AUTOSAR XML (schema 4-2-2)
package /CDD_CORE5
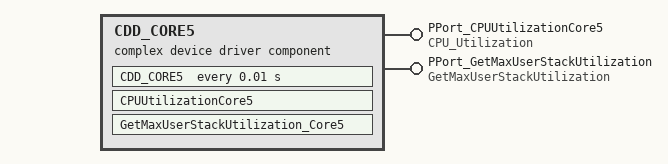
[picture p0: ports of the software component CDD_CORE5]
  complex device driver sw component type CDD_CORE5
    provide port PPort_CPUUtilizationCore5: provided-interface=CPU_Utilization
    provide port PPort_GetMaxUserStackUtilization: provided-interface=GetMaxUserStackUtilization
    behavior SwcInternalBehavior
      operation invoked event OperationInvokedEvent_0: start-on-event=CPUUtilizationCore5, operation=PPort_CPUUtilizationCore5.CPU_Utilization
      timing event TimingEvent_0: start-on-event=CDD_CORE5, period=0.01
      operation invoked event OperationInvokedEvent_1: start-on-event=GetMaxUserStackUtilization_Core5, operation=PPort_GetMaxUserStackUtilization.GetMaxUserStackUtilization
      runnable CPUUtilizationCore5: symbol=CPUUtilizationCore5_func
      runnable CDD_CORE5: symbol=CDD_CORE5_func
      runnable GetMaxUserStackUtilization_Core5: symbol=GetMaxUserStackUtilization_Core5_func
